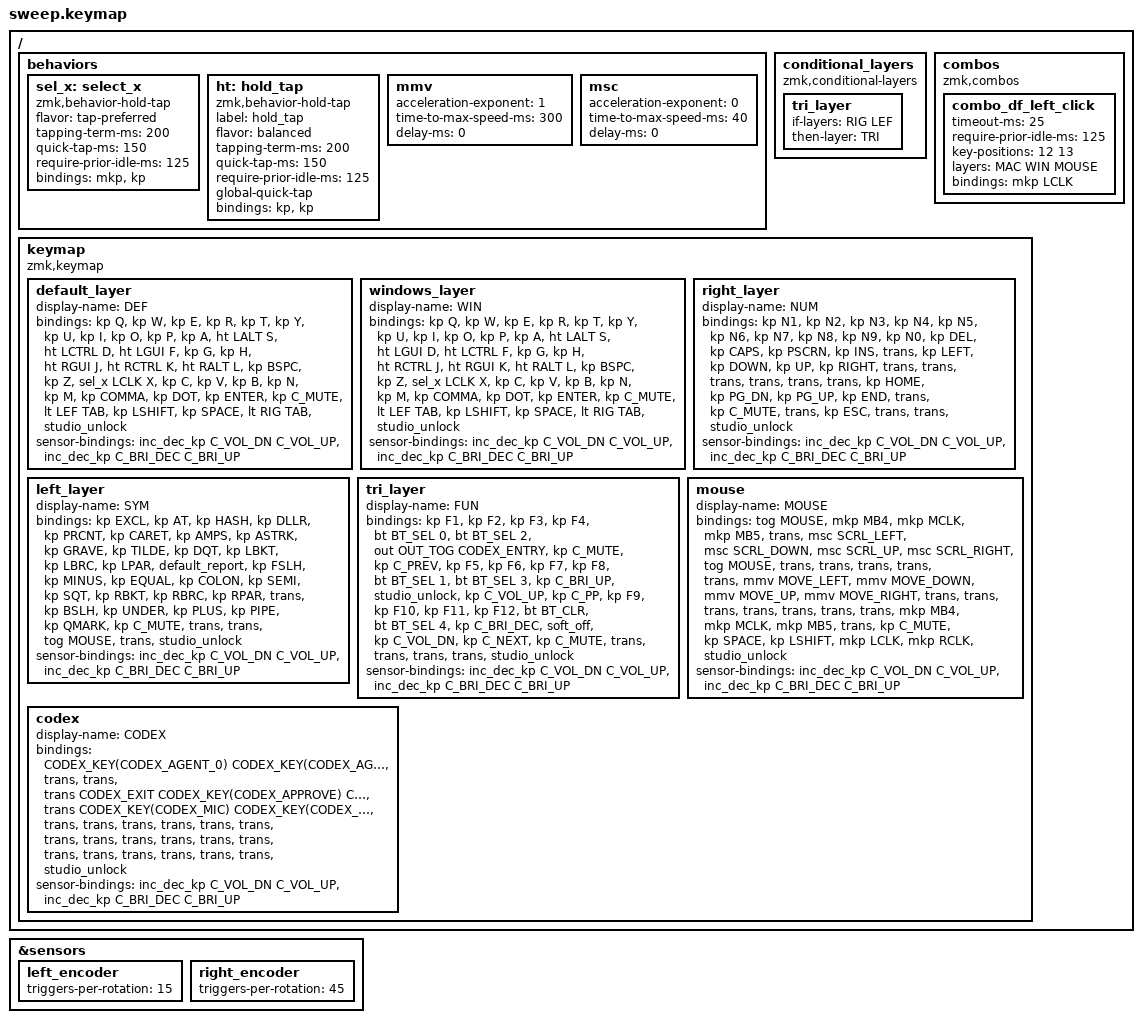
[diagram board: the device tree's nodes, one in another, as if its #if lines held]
// Copyright (c) 2022 The ZMK Contributors
// SPDX-License-Identifier: MIT
// #include <dt-bindings/zmk/rgb.h>

#define ZMK_POINTING_DEFAULT_MOVE_VAL 2500// 600
#define ZMK_POINTING_DEFAULT_SCRL_VAL 20// 10

#include <behaviors.dtsi>
#include <dt-bindings/zmk/bt.h>
#include <dt-bindings/zmk/keys.h>
#include <dt-bindings/zmk/outputs.h>
#include <dt-bindings/zmk/pointing.h>
#if defined(NXTKB_CODEX_MICRO)
#include <dt-bindings/nxtkb/codex.h>
#include <behaviors/codex_key.dtsi>
#endif

#include "behaviors/character_map.dtsi"
#include "behaviors/report.dtsi"


#define MAC 0
#define WIN 1
#define RIG 2
#define LEF 3
#define TRI 4
#define MOUSE 5
#define CODEX 6

#if defined(NXTKB_CODEX_MICRO)
#define CODEX_ENTRY &tog CODEX
#define CODEX_EXIT &tog CODEX
#define CODEX_KEY(n) &codex_key n
#else
#define CODEX_ENTRY &trans
#define CODEX_EXIT &trans
#define CODEX_KEY(n) &trans
#endif

&sensors {
	left_encoder {
		triggers-per-rotation = <15>;
	};
	right_encoder {
		triggers-per-rotation = <45>;
	};
};

/ {
	behaviors {
		sel_x: select_x {
			compatible = "zmk,behavior-hold-tap";
			#binding-cells = <2>;
			flavor = "tap-preferred";
			tapping-term-ms = <200>;
			quick-tap-ms = <150>;
			require-prior-idle-ms = <125>;
			bindings = <&mkp>, <&kp>;
		};
	
		ht: hold_tap {
			label = "hold_tap";
			compatible = "zmk,behavior-hold-tap";
			#binding-cells = <2>;
			flavor = "balanced";
			tapping-term-ms = <200>;
			quick-tap-ms = <150>;
			require-prior-idle-ms = <125>;
			global-quick-tap;
			bindings = <&kp>, <&kp>;
		};
		mmv {
			acceleration-exponent = <1>;// 1
			time-to-max-speed-ms = <300>;// 40
			delay-ms = <0>;// 0
		};
		msc {
			acceleration-exponent = <0>;// 0
			time-to-max-speed-ms = <40>;// 500
			delay-ms = <0>;// 10
		};
	};
	
	conditional_layers {
		compatible = "zmk,conditional-layers";
		
		tri_layer {
			if-layers = <RIG LEF>;
			then-layer = <TRI>;
		};
	};

	combos {
		compatible = "zmk,combos";

		combo_df_left_click {
			timeout-ms = <25>;
			require-prior-idle-ms = <125>;
			key-positions = <12 13>;
			layers = <MAC WIN MOUSE>;
			bindings = <&mkp LCLK>;
		};
	};
	
	keymap {
		compatible = "zmk,keymap";
		
		default_layer {
			display-name = "DEF";
			bindings = <
			&kp Q   &kp W       &kp E        &kp R        &kp T        &kp Y      &kp U        &kp I        &kp O       &kp P
			&kp A   &ht LALT S  &ht LCTRL D  &ht LGUI F   &kp G         &kp H      &ht RGUI J   &ht RCTRL K  &ht RALT L  &kp BSPC
			&kp Z   &sel_x LCLK X       &kp C        &kp V        &kp B         &kp N      &kp M        &kp COMMA    &kp DOT     &kp ENTER
			&kp C_MUTE  &lt LEF TAB  &kp LSHIFT    &kp SPACE  &lt RIG TAB   &studio_unlock
			>;
			sensor-bindings = <&inc_dec_kp C_VOL_DN C_VOL_UP &inc_dec_kp C_BRI_DEC C_BRI_UP>;
		};
		
		windows_layer {
			display-name = "WIN";
			bindings = <
			&kp Q  &kp W       &kp E       &kp R        &kp T         &kp Y      &kp U        &kp I       &kp O       &kp P
			&kp A  &ht LALT S  &ht LGUI D  &ht LCTRL F  &kp G         &kp H      &ht RCTRL J  &ht RGUI K  &ht RALT L  &kp BSPC
			&kp Z  &sel_x LCLK X       &kp C       &kp V        &kp B         &kp N      &kp M        &kp COMMA   &kp DOT     &kp ENTER
			&kp C_MUTE  &lt LEF TAB  &kp LSHIFT     &kp SPACE &lt RIG TAB  &studio_unlock
			>;
			sensor-bindings = <&inc_dec_kp C_VOL_DN C_VOL_UP &inc_dec_kp C_BRI_DEC C_BRI_UP>;
		};
		
		right_layer {
			display-name = "NUM";
			bindings = <
			&kp N1   &kp N2    &kp N3     &kp N4   &kp N5     &kp N6  &kp N7    &kp N8     &kp N9     &kp N0
			&kp DEL  &kp CAPS  &kp PSCRN  &kp INS  &trans     &kp LEFT  &kp DOWN   &kp UP  &kp RIGHT &trans
			&trans   &trans    &trans     &trans   &trans     &kp HOME  &kp PG_DN  &kp PG_UP  &kp END &trans
			&kp C_MUTE &trans   &kp ESC   &trans  &trans &studio_unlock
			>;
			sensor-bindings = <&inc_dec_kp C_VOL_DN C_VOL_UP &inc_dec_kp C_BRI_DEC C_BRI_UP>;
		};
		
		left_layer {
			display-name = "SYM";
			bindings = <
			&kp EXCL  &kp AT    &kp HASH  &kp DLLR  &kp PRCNT    &kp CARET  &kp AMPS   &kp ASTRK  &kp GRAVE  &kp TILDE
			&kp DQT   &kp LBKT  &kp LBRC  &kp LPAR  &default_report     &kp FSLH   &kp MINUS  &kp EQUAL  &kp COLON  &kp SEMI
			&kp SQT   &kp RBKT  &kp RBRC  &kp RPAR  &trans   &kp BSLH   &kp UNDER  &kp PLUS   &kp PIPE   &kp QMARK
			&kp C_MUTE &trans    &trans       &tog MOUSE     &trans  &studio_unlock
			>;
			sensor-bindings = <&inc_dec_kp C_VOL_DN C_VOL_UP &inc_dec_kp C_BRI_DEC C_BRI_UP>;
		};
		
		tri_layer {
			display-name = "FUN";
			bindings = <
			&kp F1  &kp F2   &kp F3   &kp F4   &bt BT_SEL 0    &bt BT_SEL 2  &out OUT_TOG   CODEX_ENTRY  &kp C_MUTE    &kp C_PREV
			&kp F5  &kp F6   &kp F7   &kp F8   &bt BT_SEL 1    &bt BT_SEL 3  &kp C_BRI_UP   &studio_unlock    &kp C_VOL_UP  &kp C_PP
			&kp F9  &kp F10  &kp F11  &kp F12  &bt BT_CLR      &bt BT_SEL 4  &kp C_BRI_DEC  &soft_off     &kp C_VOL_DN  &kp C_NEXT
			&kp C_MUTE  &trans   &trans          &trans        &trans  &studio_unlock
			>;
			sensor-bindings = <&inc_dec_kp C_VOL_DN C_VOL_UP &inc_dec_kp C_BRI_DEC C_BRI_UP>;
		};
	
		mouse {
			display-name = "MOUSE";
			bindings = <
			&tog MOUSE  &mkp MB4  &mkp MCLK  &mkp MB5   &trans      &msc SCRL_LEFT     &msc SCRL_DOWN    &msc SCRL_UP     &msc SCRL_RIGHT    &tog MOUSE
			&trans      &trans    &trans     &trans     &trans      &mmv MOVE_LEFT     &mmv MOVE_DOWN    &mmv MOVE_UP     &mmv MOVE_RIGHT    &trans
			&trans      &trans    &trans     &trans     &trans      &trans     &mkp MB4  &mkp MCLK  &mkp MB5  &trans
			&kp C_MUTE &kp SPACE  &kp LSHIFT  &mkp LCLK  &mkp RCLK &studio_unlock
			>;
			sensor-bindings = <&inc_dec_kp C_VOL_DN C_VOL_UP &inc_dec_kp C_BRI_DEC C_BRI_UP>;
		};
#if defined(NXTKB_CODEX_MICRO)
		codex {
			display-name = "CODEX";
			bindings = <
			CODEX_KEY(CODEX_AGENT_0)  CODEX_KEY(CODEX_AGENT_1)  CODEX_KEY(CODEX_AGENT_2)  CODEX_KEY(CODEX_AGENT_3)  CODEX_KEY(CODEX_AGENT_4)  CODEX_KEY(CODEX_AGENT_5)  &trans  &trans  &trans  CODEX_EXIT
			CODEX_KEY(CODEX_APPROVE)  CODEX_KEY(CODEX_SPLIT)  CODEX_KEY(CODEX_DECLINE)  CODEX_KEY(CODEX_FAST)  &trans  CODEX_KEY(CODEX_MIC)  CODEX_KEY(CODEX_SEND)  &trans  &trans  &trans
			&trans  &trans  &trans         &trans         &trans           &trans         &trans         &trans         &trans  &trans
			&trans  &trans  &trans         &trans         &trans           &studio_unlock
			>;
			sensor-bindings = <&inc_dec_kp C_VOL_DN C_VOL_UP &inc_dec_kp C_BRI_DEC C_BRI_UP>;
		};
#endif
	};
};
